# GD32A503 register map
File version: 1.0
CPU: CM33 r0p4, little endian, MPU, FPU, 4 interrupt priority bits
Registers are 32-bit, read-write, reset 0x0 unless marked. A register's access mark holds for its fields unless they carry their own. Offsets are from the block's base; [hi:lo] are bit positions; {n}, {i} and the like mark numbered series.

## SPI0 — Serial peripheral interface
Base 0x40013000
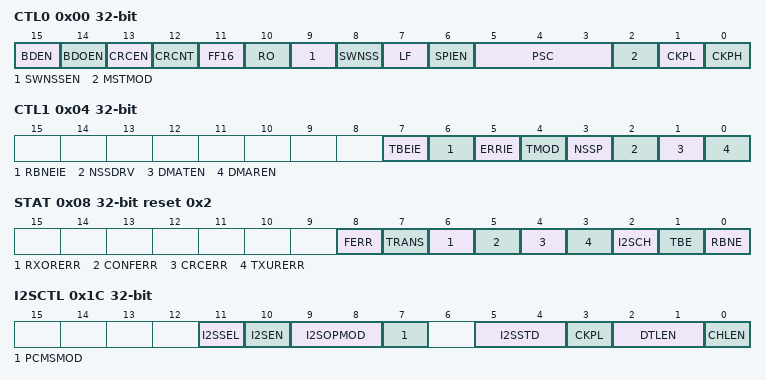
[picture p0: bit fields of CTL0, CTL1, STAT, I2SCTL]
0x00 CTL0 — control register 0
  [15] BDEN — Bidirectional enable
  [14] BDOEN — Bidirectional Transmit output enable
  [13] CRCEN — CRC Calculation Enable
  [12] CRCNT — CRC Next Transfer
  [11] FF16 — Data frame format
  [10] RO — Receive only
  [9] SWNSSEN — NSS Software Mode Selection
  [8] SWNSS — NSS Pin Selection In NSS Software Mode
  [7] LF — LSB First Mode
  [6] SPIEN — SPI enable
  [5:3] PSC — Master Clock Prescaler Selection
  [2] MSTMOD — Master Mode Enable
  [1] CKPL — Clock polarity Selection
  [0] CKPH — Clock Phase Selection
0x04 CTL1 — control register 1
  [7] TBEIE — Tx buffer empty interrupt enable
  [6] RBNEIE — RX buffer not empty interrupt enable
  [5] ERRIE — Error interrupt enable
  [4] TMOD — SPI TI Mode Enable
  [3] NSSP — SPI NSS pulse mode Enable
  [2] NSSDRV — Drive NSS Output
  [1] DMATEN — Transmit Buffer DMA Enable
  [0] DMAREN — Rx buffer DMA enable
0x08 STAT access per field reset 0x2 — status register
  [8] FERR rw — Format Error
  [7] TRANS ro — Transmitting On-going Bit
  [6] RXORERR ro — Reception Overrun Error Bit
  [5] CONFERR ro — SPI Configuration error
  [4] CRCERR rw — SPI CRC Error Bit
  [3] TXURERR ro — Transmission underrun error bit
  [2] I2SCH ro — I2S channel side
  [1] TBE ro — Transmit Buffer Empty
  [0] RBNE ro — Receive Buffer Not Empty
0x0C DATA
  [15:0] SPI_DATA — Data transfer register
0x10 CRCPOLY reset 0x7 — CRC polynomial register
  [15:0] CRCPOLY
0x14 RCRC ro — RX CRC register
  [15:0] RCRC
0x18 TCRC ro — TX CRC register
  [15:0] TCRC — Tx CRC register
0x1C I2SCTL — I2S control register
  [11] I2SSEL — I2S mode selection
  [10] I2SEN — I2S Enable
  [9:8] I2SOPMOD — I2S operation mode
  [7] PCMSMOD — PCM frame synchronization mode
  [5:4] I2SSTD — I2S standard selection
  [3] CKPL — Idle state clock polarity
  [2:1] DTLEN — Data length
  [0] CHLEN — Channel length (number of bits per audio channel)
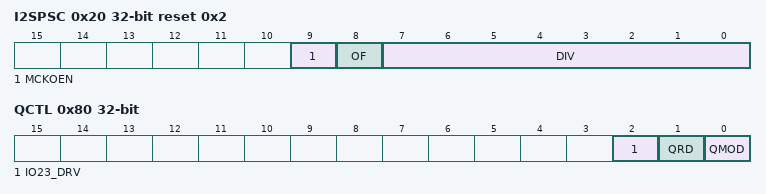
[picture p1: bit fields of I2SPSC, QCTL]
0x20 I2SPSC reset 0x2 — I2S prescaler register
  [9] MCKOEN — I2S_MCK output enable
  [8] OF — Odd factor for the prescaler
  [7:0] DIV — Dividing factor for the prescaler
0x80 QCTL — Quad-SPI mode control register
  [2] IO23_DRV — Drive IO2 and IO3 enable
  [1] QRD — Quad-SPI mode read select
  [0] QMOD — Quad-SPI mode enable

## SPI1 — Serial peripheral interface
Base 0x40003800
Registers as SPI0, without QCTL.

## CMP — Comparator
Base 0x40017C00
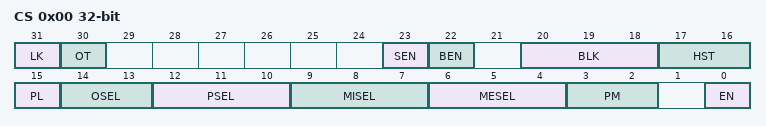
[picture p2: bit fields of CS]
0x00 CS access per field — CMP control and status register
  [31] LK rw — Comparator lock
  [30] OT ro — CMP output
  [23] SEN rw — Voltage scaler enable bit
  [22] BEN rw — Scaler bridge enable bit
  [20:18] BLK rw — CMP output blanking source
  [17:16] HST rw — CMP hysteresis
  [15] PL rw — Polarity of comparator output
  [14:13] OSEL rw — Comparator output selection
  [12:10] PSEL rw — CMP_IP input selection
  [9:7] MISEL rw — CMP_IM internal input selection
  [6:4] MESEL rw — Comparator 0 input selection
  [3:2] PM rw — CMP0 power mode
  [0] EN rw — Comparator 0 enable

## BKP — Backup registers
Base 0x40006C00
{0x4+4i} DATA{i} (i=0..9) — Backup data register {i}
  [15:0] DATA — Backup data
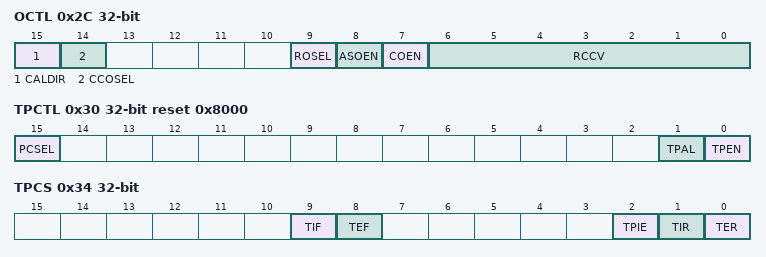
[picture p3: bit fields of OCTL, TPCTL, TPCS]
0x2C OCTL — RTC signal output control register
  [15] CALDIR — RTC clock calibration direction
  [14] CCOSEL — RTC clock output selection
  [9] ROSEL — RTC output selection
  [8] ASOEN — RTC alarm or second signal output enable
  [7] COEN — RTC clock calibration output enable
  [6:0] RCCV — RTC clock calibration value
0x30 TPCTL reset 0x8000 — Tamper pin control register
  [15] PCSEL — OSC32_IN pin select
  [1] TPAL — TAMPER pin active level
  [0] TPEN — TAMPER detection enable
0x34 TPCS access per field — Tamper control and status register
  [9] TIF ro — Tamper interrupt flag
  [8] TEF ro — Tamper event flag
  [2] TPIE rw — Tamper interrupt enable
  [1] TIR wo — Tamper interrupt reset
  [0] TER wo — Tamper event reset
